# DMASS0_BCDMA_0_BCDMA_BCHANRT register map
Vendor: Texas Instruments
Peripheral module from a debugger description file (folder am243x).
Registers are 32-bit, access not given, reset 0x0 unless marked. A register's access mark holds for its fields unless they carry their own. Offsets are as the file gives them; lines under a group give offsets from that group; [hi:lo] are bit positions; {n}, {i} and the like mark numbered series; 'fields as' and 'values as' point back to an identical list; <NAME> marks a mode.

## DMASS0_BCDMA_0_BCDMA_BCHANRT
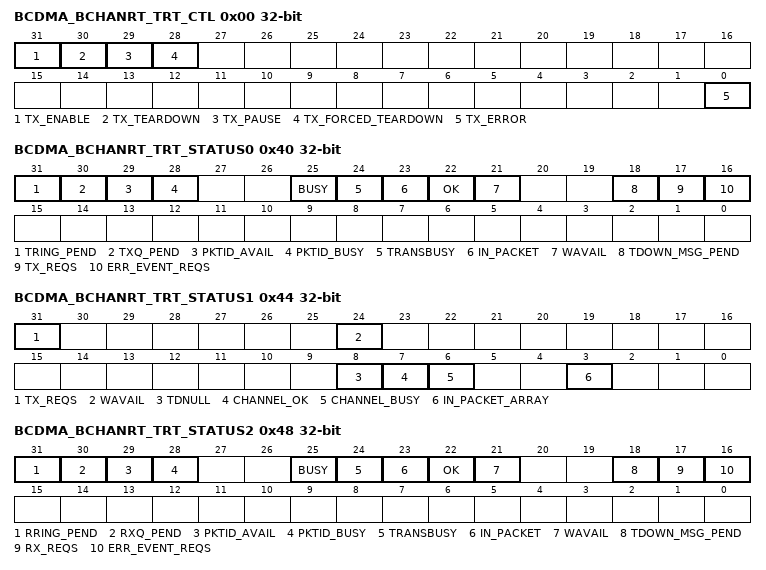
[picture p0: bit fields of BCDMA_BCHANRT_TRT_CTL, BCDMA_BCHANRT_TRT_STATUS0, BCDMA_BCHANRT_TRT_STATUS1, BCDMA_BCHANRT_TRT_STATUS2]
0x00 BCDMA_BCHANRT_TRT_CTL access per field — The Tx Channel Realtime Control Register contains real-time control and status information for the Tx DMA channel. The fields in this register can safely be changed while the channel is in operation.
  [31] TX_ENABLE rw — This field enables or disables the channel. Disabling a channel halts operation on the channel after the current block transfer is completed. Disabling a channel in the middle of a packet transfer may result in underflow conditions in the attached application block and data loss. When a channel is disabled, the implementation may choose to reset all state for the channel. The pause bit should be asserted instead of clearing enable directly if the intent is to temporarily pause the channel. This field is encoded as follows: 0 = channel is disabled 1 = channel is enabled This field will be cleared by HW after a teardown is requested to indicate that the channel teardown is complete.
  [30] TX_TEARDOWN rw — Channel teardown: Setting this bit will request the channel to be torn down. This field will remain set after a channel teardown is complete.
  [29] TX_PAUSE rw — Channel pause: Setting this bit will cause the channel to pause processing immediately.
  [28] TX_FORCED_TEARDOWN rw — Channel forced teardown: Setting this bit will cause the channel to stop waiting on trigger events. When this bit is set, the implementation may choose to bypass data transfers and event generation. This bit is a modifier to the normal tx_teardown and is intended to flush the channel to recover any descriptor or TR references which are currently being held by the BCDMA even if the trigger source is no longer functioning. Uso fo this bit is considered a 'catastrophic' condition and it is assumed that SW will need to perform some re-initialization in the system to re-align events, data buffers, etc. This bit should be set in addition to the tx_teardown bit in order to cause a forced teardown. This field will remain set after a channel teardown is complete.
  [0] TX_ERROR ro — Channel error: This bit will be set anytime an error has occurred on the channel. This bit is cleared by writing back a 0.
0x08 BCDMA_BCHANRT_TRT_SWTRIG — The Software Trigger Register provides a mechanism by which software can directly trigger the channel in a secure way. This register is only used when the tx_chan_type is configured as a Third Party DMA channel. This register has no function when the channel is configured for packet mode transfers. A write to this register will cause an event to be sent to this channel.
  [0] TRIGGER — Trigger: writing this bit with a value of 1 will cause the trigger event to be sent to this channel (access NA/W)
0x40 BCDMA_BCHANRT_TRT_STATUS0 ro — The Status Register provides a read only view of channel status bits.
  [31] TRING_PEND — The channel ring has a descriptor
  [30] TXQ_PEND — The channel fifo is available
  [29] PKTID_AVAIL — The channel has an available packet id
  [28] PKTID_BUSY — There is an outstanding pktid for the channel
  [25] BUSY — The channel is busy
  [24] TRANSBUSY — The channel has an outstanding transaction
  [23] IN_PACKET — The channel is currently in a packet
  [22] OK — The channel is ready to be scheduled
  [21] WAVAIL — The fifo for the channel has space to place a burst size entry
  [18] TDOWN_MSG_PEND — A teardown message is pending
  [17] TX_REQS — The channel is sending a schedule request
  [16] ERR_EVENT_REQS — The channel is trying to schedule an error event
0x44 BCDMA_BCHANRT_TRT_STATUS1 ro — The Status Register provides a read only view of channel status bits.
  [31] TX_REQS — The channel is sending a schedule request
  [24] WAVAIL — The fifo has space for a burst size
  [8] TDNULL — Channel is trying to teardown and has met conditions
  [7] CHANNEL_OK — Channel is trying to schedule a transaction
  [6] CHANNEL_BUSY — The channel is active
  [3] IN_PACKET_ARRAY — The channel is in a packet
0x48 BCDMA_BCHANRT_TRT_STATUS2 ro — The Status Register provides a read only view of channel status bits.
  [31] RRING_PEND — The channel ring has a descriptor
  [30] RXQ_PEND — The channel fifo is available
  [29] PKTID_AVAIL — The channel has an available packet id
  [28] PKTID_BUSY — There is an outstanding pktid for the channel
  [25] BUSY — The channel is busy
  [24] TRANSBUSY — The channel has an outstanding transaction
  [23] IN_PACKET — The channel is currently in a packet
  [22] OK — The channel is ready to be scheduled
  [21] WAVAIL — The fifo for the channel has space to place a burst size entry
  [18] TDOWN_MSG_PEND — A teardown message is pending
  [17] RX_REQS — The channel is sending a schedule request
  [16] ERR_EVENT_REQS — The channel is trying to schedule an error event
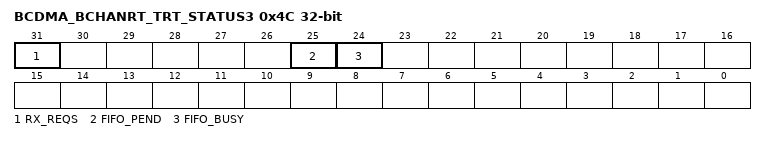
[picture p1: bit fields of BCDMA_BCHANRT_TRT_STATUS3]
0x4C BCDMA_BCHANRT_TRT_STATUS3 ro — The Status Register provides a read only view of channel status bits.
  [31] RX_REQS — The channel is sending a schedule request
  [25] FIFO_PEND — The FIFO has enough data for a burst
  [24] FIFO_BUSY — The fifo has data
0x80 BCDMA_BCHANRT_TRT_STDATA — The State Data Registers contain the current working state of the Tx DMA channel. These registers are provided so that the Host can determine the potential cause of an error or exception condition which was reported by the channel. These registers should not be accessed without reason while the BCDMA is operating as accesses will cause performance to decrease as these MMRs are just providing a window into the actual state RAM
  [31:0] STATE_INFO — See Tx state mapping table (access R/NA)
0x100 BCDMA_BCHANRT_RRT_STDATA rw — The State Data Registers contain the current working state of the Rx DMA channel. These registers are provided so that the Host can determine the potential cause of an error or exception condition which was reported by the channel. These registers should not be accessed without reason while the BCDMA is operating as accesses will cause performance to decrease as these MMRs are just providing a window into the actual state RAM
  [31:0] STATE_INFO — See Rx state mapping table
0x400 BCDMA_BCHANRT_TRT_PCNT — The statistics registers are supplied to give software applications operational progress status for the channel.
  [31:0] PCNT — Current completed packet count for the channel. (access R/WTD)
0x408 BCDMA_BCHANRT_TRT_BCNT — The statistics registers are supplied to give software applications operational progress status for the channel.
  [31:0] BCNT — Current completed payload byte count for the channel. (access R/WTD)
0x410 BCDMA_BCHANRT_TRT_SBCNT — The statistics registers are supplied to give software applications operational progress status for the channel.
  [31:0] SBCNT — Current started byte count for the channel. (access R/WTD)
